# GD32F50x register map
File version: 1.0
CPU: CM33 r2p1, little endian, MPU, FPU, 4 interrupt priority bits
Registers are 32-bit, read-write, reset 0x0 unless marked. A register's access mark holds for its fields unless they carry their own. Offsets are from the block's base; [hi:lo] are bit positions; {n}, {i} and the like mark numbered series.

## TRNG — True random number generator
Base 0x40023C00
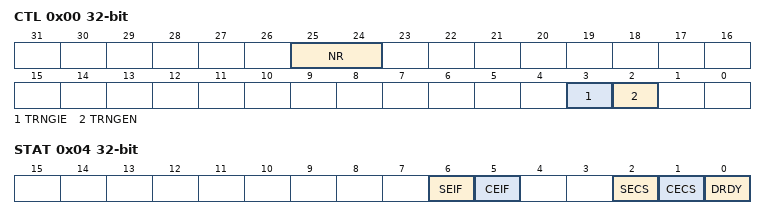
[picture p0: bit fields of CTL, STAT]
0x00 CTL — Control register
  [25:24] NR — analog rng power mode.
  [3] TRNGIE — Interrupt enabled bit. This bit controls the generation of an interrupt when DRDY, SEIF or CEIF was set.
  [2] TRNGEN — TRNG enabled bit.
0x04 STAT access per field — Status register
  [6] SEIF rw — Seed error interrupt flag
  [5] CEIF rw — Clock error interrupt flag
  [2] SECS ro — Seed error current status
  [1] CECS ro — Clock error current status
  [0] DRDY ro — Random data ready status bit. This bit is cleared by reading the TRNG_DATA register and set when a new random number is generated.
0x08 DATA ro
  [31:0] TRNGDATA — 32-bit random data

## EXMC — External memory controller
Base 0xA0000000
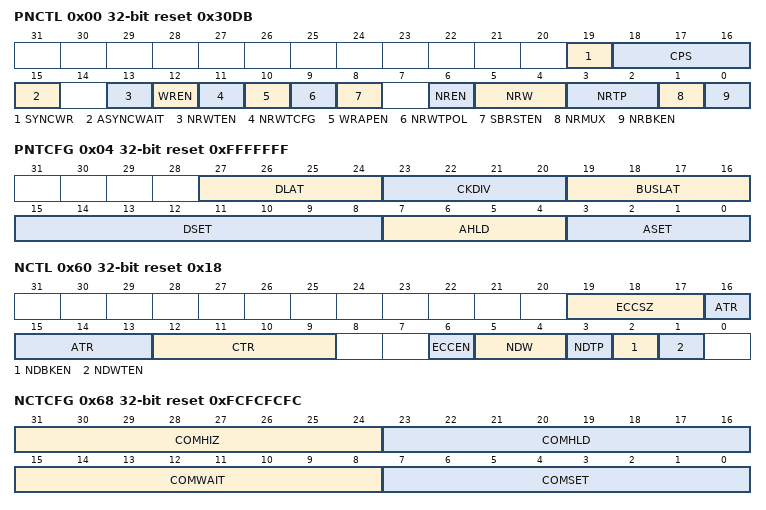
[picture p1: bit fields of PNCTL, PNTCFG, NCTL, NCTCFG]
0x00 PNCTL reset 0x30DB — PSRAM/NOR Flash control registers
  [19] SYNCWR — Synchronous write
  [18:16] CPS — CRAM page size
  [15] ASYNCWAIT — Asynchronous wait
  [13] NRWTEN — NWAIT signal enable
  [12] WREN — Write enable
  [11] NRWTCFG — NWAIT signal configuration, only work in synchronous mode
  [10] WRAPEN — Wrapped burst mode enable
  [9] NRWTPOL — NWAIT signal polarity
  [8] SBRSTEN — Synchronous burst enable
  [6] NREN — NOR Flash access enable
  [5:4] NRW — NOR region memory data bus width
  [3:2] NRTP — NOR region memory type
  [1] NRMUX — NOR region memory address/data multiplexing
  [0] NRBKEN — NOR region enable
0x04 PNTCFG reset 0xFFFFFFF — PSRAM/NOR Flash timing configuration registers
  [27:24] DLAT — Data latency for NOR Flash. Only valid in synchronous access
  [23:20] CKDIV — Synchronous clock divide ratio. This filed is only effect in synchronous mode.
  [19:16] BUSLAT — Bus latency
  [15:8] DSET — Data setup time
  [7:4] AHLD — Address hold time
  [3:0] ASET — Address setup time
0x60 NCTL reset 0x18 — NAND Flash control registers
  [19:17] ECCSZ — ECC size
  [16:13] ATR — ALE to RE delay
  [12:9] CTR — CLE to RE delay
  [6] ECCEN — ECC enable
  [5:4] NDW — NAND bank memory data bus width
  [3] NDTP — NAND bank memory type
  [2] NDBKEN — NAND bank enable
  [1] NDWTEN — Wait function enable
0x64 NSTAT ro reset 0x42 — NAND Flash state registers
  [6] FFEPT — FIFO empty flag
0x68 NCTCFG reset 0xFCFCFCFC — NAND Flash common space timing configuration registers
  [31:24] COMHIZ — Common memory data bus HiZ time
  [23:16] COMHLD — Common memory hold time
  [15:8] COMWAIT — Common memory wait time
  [7:0] COMSET — Common memory setup time
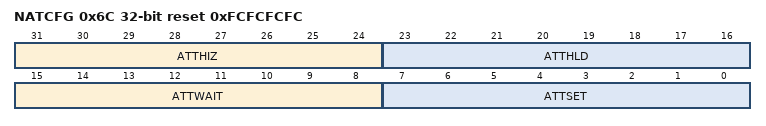
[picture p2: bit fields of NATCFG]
0x6C NATCFG reset 0xFCFCFCFC — NAND Flash attribute space timing configuration registers
  [31:24] ATTHIZ — Attribute memory data bus HiZ time
  [23:16] ATTHLD — Attribute memory hold time
  [15:8] ATTWAIT — Attribute memory wait time
  [7:0] ATTSET — Attribute memory setup time
0x74 NECC ro — NAND Flash ECC registers
  [31:0] ECC — ECC result

## EXTI — External interrupt/event controller
Base 0x40010400
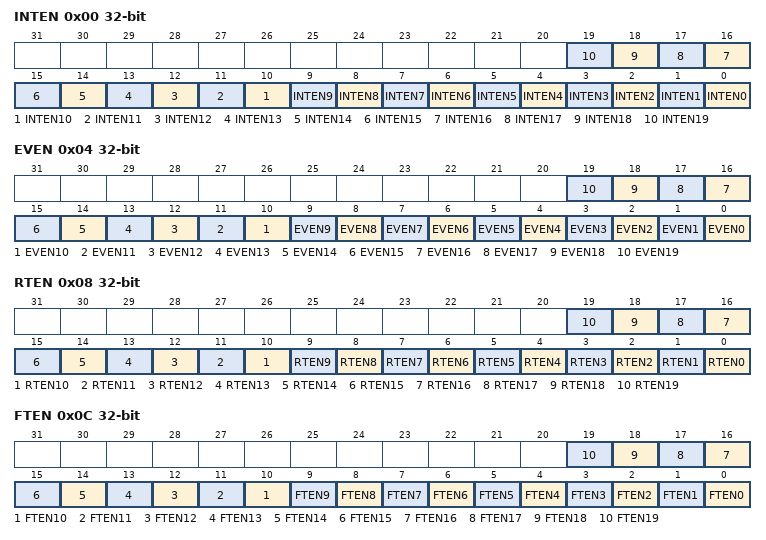
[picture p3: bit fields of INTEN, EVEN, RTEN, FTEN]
0x00 INTEN — Interrupt enable register (EXTI_INTEN)
  [n] INTEN{n} (n=0..19) — Enable Interrupt on line {n}
0x04 EVEN — Event enable register (EXTI_EVEN)
  [n] EVEN{n} (n=0..19) — Enable Event on line {n}
0x08 RTEN — Rising Edge Trigger Enable register (EXTI_RTEN)
  [n] RTEN{n} (n=0..19) — Rising edge trigger enable of line {n}
0x0C FTEN — Falling Egde Trigger Enable register (EXTI_FTEN)
  [n] FTEN{n} (n=0..19) — Falling edge trigger enable of line {n}
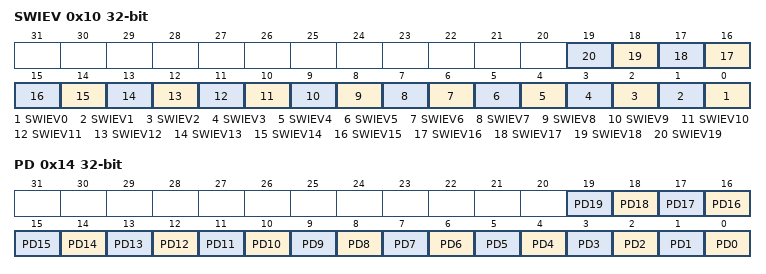
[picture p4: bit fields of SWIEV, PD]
0x10 SWIEV — Software interrupt event register (EXTI_SWIEV)
  [n] SWIEV{n} (n=0..19) — Interrupt/Event software trigger on line {n}
0x14 PD — Pending register (EXTI_PD)
  [n] PD{n} (n=0..19) — Interrupt pending status of line {n}

## FMC — Flash memory controller
Base 0x40022000
0x04 KEY0 wo — Unlock key register
  [31:0] KEY — FMC_CTL0 unlock register
0x08 OBKEY wo — Option byte unlock key register
  [31:0] OBKEY — Option bytes operation unlock register.
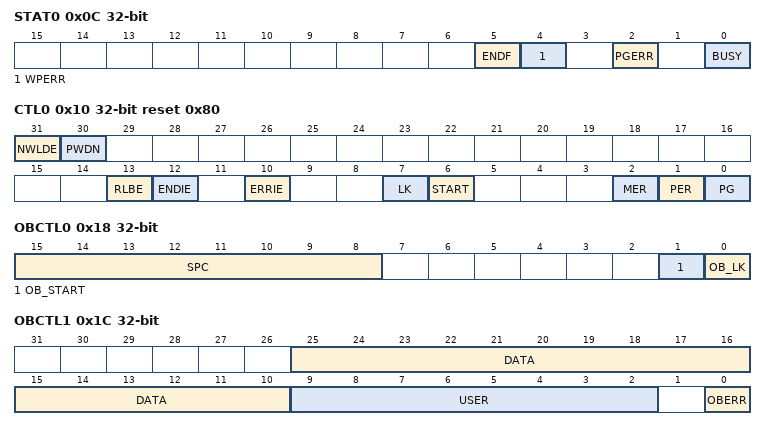
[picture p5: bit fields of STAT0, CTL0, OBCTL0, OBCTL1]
0x0C STAT0 — Status register 0
  [5] ENDF — End of operation flag bit
  [4] WPERR — Erase/Program protection error flag bit
  [2] PGERR — Program error flag bit
  [0] BUSY — The flash is busy bit
0x10 CTL0 access per field reset 0x80 — Control register
  [31] NWLDE rw — Enable no waiting time area load when system reset. No waiting time area load include load option bytes, OTP, main flash code area.
  [30] PWDN rw — Flash enter to Deep Power Down mode when no operation.
  [13] RLBE wo — Enable read lock block for OTP2.
  [12] ENDIE rw — End of operation interrupt enable bit
  [10] ERRIE rw — Error interrupt enable bit
  [7] LK rw — FMC_CTL0 lock bit
  [6] START rw — Send erase command to FMC bit
  [2] MER rw — Main flash mass erase for bank0 command bit
  [1] PER rw — Main flash page erase for bank0 command bit
  [0] PG rw — Main flash program for bank0 command bit
0x14 ADDR0 wo — Address register 0
  [31:0] ADDR — Flash erase command address bits
0x18 OBCTL0 — Option byte control register 0
  [15:8] SPC — Option byte security protection code.
  [1] OB_START — Send option byte change command to FMC bit.
  [0] OB_LK — FMC_OBCTL0/1/2 lock bit
0x1C OBCTL1 access per field — Option byte control register 1
  [25:10] DATA rw — Store DATA of option bytes block after system reset.
  [9:2] USER rw — Store USER of option bytes block after system reset.
  [0] OBERR ro — Option bytes read error bit.
0x20 OBCTL2 — Option byte control register 2
  [31:0] WP — Store WP of option bytes block after system reset.
0x24 OTP1CFG reset 0xFFFF — OTP1 configuration register
  [15:0] OTP1REN — OTP1 read enable.
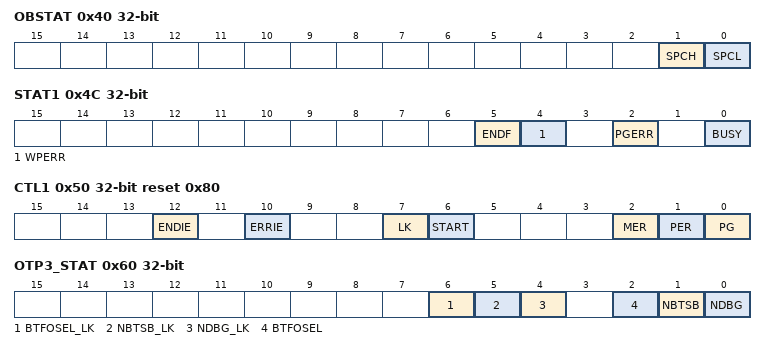
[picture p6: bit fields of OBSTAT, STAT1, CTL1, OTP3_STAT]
0x40 OBSTAT ro — Option bytes status register
  [1] SPCH — Security protection is level high now.
  [0] SPCL — Security protection is level low now.
0x44 KEY1 wo — Unlock key register
  [31:0] KEY — FMC_CTL1 unlock register
0x4C STAT1 — Status register 1
  [5] ENDF — End of operation flag bit
  [4] WPERR — Erase/Program protection error flag bit
  [2] PGERR — Program error flag bit
  [0] BUSY — The flash is busy bit.
0x50 CTL1 reset 0x80 — Control register
  [12] ENDIE — End of operation interrupt enable bit
  [10] ERRIE — Error interrupt enable bit
  [7] LK — FMC_CTL1 lock bit
  [6] START — Send erase command to FMC bit
  [2] MER — Main flash mass erase for bank1 command bit
  [1] PER — Main flash page erase for bank1 command bit
  [0] PG — Main flash program for bank1 command bit
0x54 ADDR1 wo — Address register 1
  [31:0] ADDR — Flash erase command address bits
0x60 OTP3_STAT ro — OTP3 status register
  [6] BTFOSEL_LK — BTFOSEL lock status.
  [5] NBTSB_LK — NBTSB lock status.
  [4] NDBG_LK — NDBG lock status.
  [2] BTFOSEL — Select Boot from flash or OTP1. This bit actives when NBTSB is 1 or BOOT0 is 0.
  [1] NBTSB — Not boot from SRAM or bootloader.
  [0] NDBG — Debugging permission setting.
0x100 PID ro — Product ID register
  [31:0] PID — Product reserved ID code register
